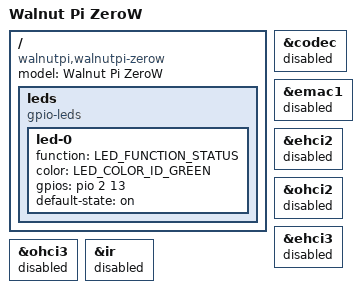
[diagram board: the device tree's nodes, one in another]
// SPDX-License-Identifier: (GPL-2.0+ OR MIT)
/*
 * Walnut Pi ZeroW: compact Walnut Pi 1 family board. Micro HDMI,
 * 2x USB-C (USB0 = OTG/power, USB1 = second port on ehci1/ohci1),
 * 40-pin header, status LED on PC13. Ethernet, USB2/USB3 host,
 * line-out audio and IR live on the FPC expansion board and are
 * disabled here; attach the expansion and enable them with the
 * walnutpi-zerow-expansion overlay.
 */

/dts-v1/;

#include "sun50i-h618-walnutpi.dtsi"

/ {
	model = "Walnut Pi ZeroW";
	compatible = "walnutpi,walnutpi-zerow", "allwinner,sun50i-h618";

	leds {
		compatible = "gpio-leds";

		led-0 {
			function = LED_FUNCTION_STATUS;
			color = <LED_COLOR_ID_GREEN>;
			gpios = <&pio 2 13 GPIO_ACTIVE_HIGH>; /* PC13 */
			default-state = "on";
		};
	};
};

/* line-out is only on the FPC expansion board */
&codec {
	status = "disabled";
};

/* 100M Ethernet is only on the FPC expansion board */
&emac1 {
	status = "disabled";
};

/* USB2/USB3 host ports are only on the FPC expansion board */
&ehci2 {
	status = "disabled";
};

&ohci2 {
	status = "disabled";
};

&ehci3 {
	status = "disabled";
};

&ohci3 {
	status = "disabled";
};

/* IR receiver is only on the FPC expansion board */
&ir {
	status = "disabled";
};
